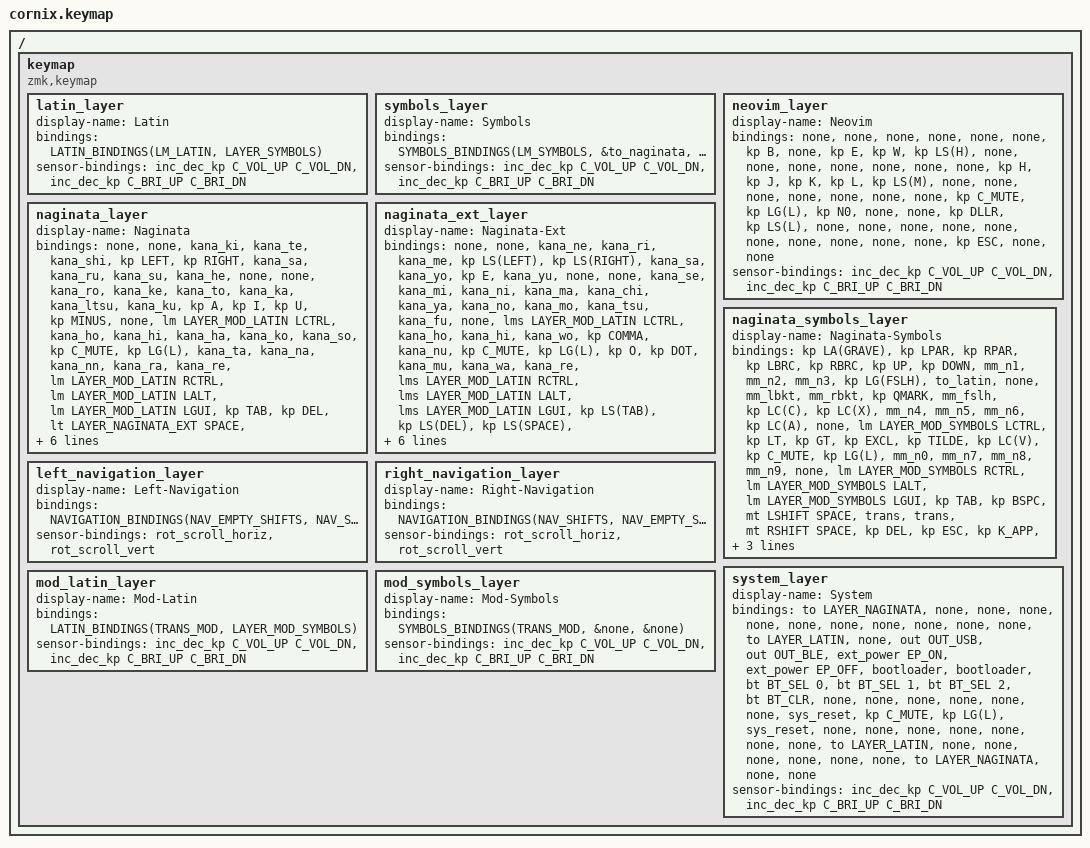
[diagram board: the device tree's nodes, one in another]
/*
 * Copyright (c) 2020 The ZMK Contributors
 *
 * SPDX-License-Identifier: MIT
 */

#include "zmk-helpers/helper.h"
#include "includes/cornix54.h"
#include "includes/base_keys.h"
#include "includes/navigation_keys.h"
#include "includes/layers.h"
#include "includes/settings.h"
#include <behaviors.dtsi>
#include <dt-bindings/zmk/bt.h>
#include <dt-bindings/zmk/ext_power.h>
#include <dt-bindings/zmk/keys.h>
#include <dt-bindings/zmk/outputs.h>
#include <dt-bindings/zmk/pointing.h>

#include "includes/combos.dtsi"
#include "includes/naginata_macros.dtsi"
#include "includes/naginata_combos.dtsi"
#include "includes/behaviors.dtsi"

/ {
    keymap {
        compatible = "zmk,keymap";

        latin_layer {
            display-name = "Latin";

            // ------------------------------------------------------------------------------------------------------------
            // |       |   B   |  L  |  D  |  W   |  Z   |                   | , !  |  F   |  O   |  U   |  J   |       |
            // |   `   |   N   |  R  |  T  |  S   |  G   |                   |  Y   |  H   |  A   |  E   |  I   |   '   |
            // |LM8/CTL|   Q   |  X  |  P  |  C   |  V   |        |  |       |  K   |  M   | . ?  | - _  | / \  |LM8/CTL|
            // |LM8/ALT|LM8/GUI| TAB | DEL |SFT/SP|L1/RET|                   |L1/RET|SFT/SP| BSPC | ESC  | MENU |LM8/ALT|
            // ------------------------------------------------------------------------------------------------------------

            bindings = <
LATIN_BINDINGS(LM_LATIN, LAYER_SYMBOLS)
            >;
            sensor-bindings = <&inc_dec_kp C_VOL_UP C_VOL_DN &inc_dec_kp C_BRI_UP C_BRI_DN>;
        };

        symbols_layer {
            display-name = "Symbols";

            // ------------------------------------------------------------------------------------------------------------
            // | TO_JA |   {   |  }  |  [   |  ]   |  ^   |                   |  %   |  #   |  <  |  >  |  $   |IME_TG |
            // |       |   ;   |  |  |  &   |  0   |  :   |                   |  @   |  1   |  (  |  )  |  =   |       |
            // |LM9/CTL|   6   |  7  |  8   |  9   |  +   |        |  |       |  *   |  2   |  3  |  4  |  5   |LM9/CTL|
            // |LM9/ALT|LM9/GUI| TAB | BSPC |SFT/SP| (RET)|                   | (RET)|SFT/SP| DEL | ESC | MENU |LM9/ALT|
            // ------------------------------------------------------------------------------------------------------------

            bindings = <
SYMBOLS_BINDINGS(LM_SYMBOLS, &to_naginata, &kp LA(GRAVE))
            >;
            sensor-bindings = <&inc_dec_kp C_VOL_UP C_VOL_DN &inc_dec_kp C_BRI_UP C_BRI_DN>;
        };

        neovim_layer {
            display-name = "Neovim";

            // ------------------------------------------------------------------------------------------------------------
            // |       |     |     |      |      |      |                   |  b   |      |  e   |  w   |  H   |      |
            // |       |     |     |      |      |      |                   |  h   |  j   |  k   |  l   |  M   |      |
            // |       |     |     |      |      |      |        |  |       |  0   |      |      |  $   |  L   |      |
            // |       |     |     |      |      |      |                   |      |      |      | ESC  |      |      |
            // ------------------------------------------------------------------------------------------------------------

            bindings = <
&none   &none   &none   &none   &none   &none                   &kp B   &none   &kp E  &kp W      &kp LS(H)  &none
&none   &none   &none   &none   &none   &none                   &kp H   &kp J   &kp K  &kp L      &kp LS(M)  &none
&none   &none   &none   &none   &none   &none   &kp C_MUTE &kp LG(L)   &kp N0  &none   &none  &kp DLLR   &kp LS(L)  &none
&none   &none   &none   &none   &none   &none                   &none   &none   &none  &kp ESC    &none      &none
            >;
            sensor-bindings = <&inc_dec_kp C_VOL_UP C_VOL_DN &inc_dec_kp C_BRI_UP C_BRI_DN>;
        };

        naginata_layer {
            display-name = "Naginata";

            // ------------------------------------------------------------------------------------------------------------
            // |       |       |  き  |  て  |  し  |  <- |                   |  ->  |  さ  |  る  |  す  |  へ  |       |
            // |       |   ろ  |  け  |  と  |  か  |  っ  |                   |  く  |  あ  |  い  |  う  |  ー  |       |
            // |LM8/CTL|   ほ  |  ひ  |  は  |  こ  |  そ  |        |  |       |  た  |  な  |  ん  |  ら  |  れ  |LM8/CTL|
            // |LM8/ALT|LM8/GUI| TAB | DEL  |L4/SP |L5/RET|                  |L5/RET|L4/SP| BSPC | ESC  | MENU |LM8/ALT|
            // ------------------------------------------------------------------------------------------------------------

            bindings = <
&none                   &none                 &kana_ki  &kana_te  &kana_shi  &kp LEFT                   &kp RIGHT  &kana_sa  &kana_ru  &kana_su     &kana_he   &none
&none                   &kana_ro              &kana_ke  &kana_to  &kana_ka   &kana_ltsu                 &kana_ku   &kp A     &kp I     &kp U        &kp MINUS  &none
&lm LAYER_MOD_LATIN LCTRL &kana_ho              &kana_hi  &kana_ha  &kana_ko   &kana_so   &kp C_MUTE &kp LG(L) &kana_ta   &kana_na  &kana_nn  &kana_ra     &kana_re   &lm LAYER_MOD_LATIN RCTRL
&lm LAYER_MOD_LATIN LALT  &lm LAYER_MOD_LATIN LGUI &kp TAB  &kp DEL &lt LAYER_NAGINATA_EXT SPACE &lt LAYER_NAGINATA_SYMBOLS RET  &lt LAYER_NAGINATA_SYMBOLS RET &lt LAYER_NAGINATA_EXT SPACE &kp BSPC &kp ESC &kp K_APP &lm LAYER_MOD_LATIN RALT
            >;
            sensor-bindings = <&inc_dec_kp C_VOL_UP C_VOL_DN &inc_dec_kp C_BRI_UP C_BRI_DN>;
        };

        naginata_ext_layer {
            display-name = "Naginata-Ext";

            // ------------------------------------------------------------------------------------------------------------
            // |        |        |  ね  |  り  |  め  |   S+<- |                   |  S+->  |  さ  |  よ   |  え  |  ゆ  |       |
            // |        |   せ   |  み  |  に  |  ま  |    ち   |                   |   や   |  の  |  も   |  つ  |  ふ  |       |
            // |LMS8/CTL|   ほ   |  ひ  |  を  |  、  |    ぬ   |        |  |       |   お   |  。  |  む   |  わ  |  れ  |LMS8/CTL|
            // |LMS8/ALT|LMS8/GUI|S+TAB|S+DEL | S+SP |L5/S+RET|                   |L5/S+RET| S+SP |S+BSPC| S+ESC|S+MENU|LMS8/ALT|
            // ------------------------------------------------------------------------------------------------------------

            bindings = <
&none                   &none                  &kana_ne  &kana_ri  &kana_me   &kp LS(LEFT)               &kp LS(RIGHT)  &kana_sa  &kana_yo  &kp E      &kana_yu  &none
&none                   &kana_se               &kana_mi  &kana_ni  &kana_ma   &kana_chi                  &kana_ya       &kana_no  &kana_mo  &kana_tsu  &kana_fu  &none
&lms LAYER_MOD_LATIN LCTRL &kana_ho              &kana_hi  &kana_wo  &kp COMMA  &kana_nu   &kp C_MUTE &kp LG(L) &kp O  &kp DOT   &kana_mu  &kana_wa   &kana_re  &lms LAYER_MOD_LATIN RCTRL
&lms LAYER_MOD_LATIN LALT  &lms LAYER_MOD_LATIN LGUI &kp LS(TAB) &kp LS(DEL) &kp LS(SPACE)  &lt LAYER_NAGINATA_SYMBOLS LS(RET)  &lt LAYER_NAGINATA_SYMBOLS LS(RET)  &kp LS(SPACE)  &kp LS(BSPC) &kp LS(ESC) &kp LS(K_APP) &lms LAYER_MOD_LATIN RALT
            >;
            sensor-bindings = <&inc_dec_kp C_VOL_UP C_VOL_DN &inc_dec_kp C_BRI_UP C_BRI_DN>;
        };

        naginata_symbols_layer {
            display-name = "Naginata-Symbols";

            // ------------------------------------------------------------------------------------------------------------
            // |IME_TG |   (   | ) |  {   |  }   |  UP  |                   | DOWN |  1   |  2   |  3   |RECONV|TO_LATIN|
            // |       |   [   | ] |  ?   |  ・  |CPY(C)|                   |CUT(X)|  4   |  5   |  6   |ALL(A)|       |
            // |LM10/CTL|  <   | > |  !   |  ~   |PST(V)|        |  |       |  0   |  7   |  8   |  9   |      |LM10/CTL|
            // |LM10/ALT|LM10/GUI|TAB|BSPC|SFT/SP|(RET)|                   | (RET)|SFT/SP| DEL  | ESC  | MENU |LM10/ALT|
            // ------------------------------------------------------------------------------------------------------------

            bindings = <
&kp LA(GRAVE)               &kp LPAR                  &kp RPAR &kp LBRC  &kp RBRC  &kp UP                    &kp DOWN  &mm_n1  &mm_n2  &mm_n3  &kp LG(FSLH) &to_latin
&none                       &mm_lbkt                  &mm_rbkt &kp QMARK &mm_fslh  &kp LC(C)                 &kp LC(X) &mm_n4  &mm_n5  &mm_n6  &kp LC(A)    &none
&lm LAYER_MOD_SYMBOLS LCTRL &kp LT                    &kp GT   &kp EXCL  &kp TILDE &kp LC(V)  &kp C_MUTE &kp LG(L) &mm_n0  &mm_n7  &mm_n8  &mm_n9  &none        &lm LAYER_MOD_SYMBOLS RCTRL
&lm LAYER_MOD_SYMBOLS LALT  &lm LAYER_MOD_SYMBOLS LGUI &kp TAB &kp BSPC  &mt LSHIFT SPACE &trans     &trans  &mt RSHIFT SPACE  &kp DEL  &kp ESC &kp K_APP &lm LAYER_MOD_SYMBOLS RALT
            >;
            sensor-bindings = <&inc_dec_kp C_VOL_UP C_VOL_DN &inc_dec_kp C_BRI_UP C_BRI_DN>;
        };

        left_navigation_layer {
            display-name = "Left-Navigation";

            // ------------------------------------------------------------------------------------------------------------
            // | TO_JA |  F1 |  F2 |  F3  |  F4  |  F5  |                   |PRTSCN| HOME |  UP  |  END |PG_UP |TO_EN |
            // | PAUSE |  F6 |  F7 |  F8  |  F9  |  F10 |                   | CAPS | LEFT | DOWN | RIGHT|PG_DN | RGUI |
            // | LCTRL | F11 |     |      |      |  F12 |        |  |       |SCRLCK|LSHIFT|      |RSHIFT|INSERT| RCTRL |
            // | LALT  | LGUI| TAB |  DEL |SFT/SP|TO_SYS|                   | RET  |SFT/SP| BSPC | ESC  | MENU | RALT |
            // ------------------------------------------------------------------------------------------------------------

            bindings = <
NAVIGATION_BINDINGS(NAV_EMPTY_SHIFTS, NAV_SHIFTS, &to LAYER_SYSTEM, &kp RET)
            >;
            sensor-bindings = <&rot_scroll_horiz &rot_scroll_vert>;
        };

        right_navigation_layer {
            display-name = "Right-Navigation";

            // ------------------------------------------------------------------------------------------------------------
            // | TO_JA |  F1 |  F2 |  F3  |  F4  |  F5  |                   |PRTSCN| HOME |  UP  |  END |PG_UP |TO_EN |
            // | PAUSE |  F6 |  F7 |  F8  |  F9  |  F10 |                   | CAPS | LEFT | DOWN | RIGHT|PG_DN | RGUI |
            // | LCTRL | F11 |LSHIFT|     |RSHIFT|  F12 |        |  |       |SCRLCK|      |      |      |INSERT| RCTRL |
            // | LALT  | LGUI| TAB |  DEL |SFT/SP| RET  |                   |TO_SYS|SFT/SP| BSPC | ESC  | MENU | RALT |
            // ------------------------------------------------------------------------------------------------------------

            bindings = <
NAVIGATION_BINDINGS(NAV_SHIFTS, NAV_EMPTY_SHIFTS, &kp RET, &to LAYER_SYSTEM)
            >;
            sensor-bindings = <&rot_scroll_horiz &rot_scroll_vert>;
        };

        system_layer {
            display-name = "System";

            // ------------------------------------------------------------------------------------------------------------
            // | TO_JA |      |     |      |      |       |                   |       |      |      |      |      | TO_EN |
            // |       |OUTUSB|OUTBLE|EP_ON|EP_OFF|BOOT(L)|                   |BOOT(R)| BT 1 | BT 2 | BT 3 |BTCLR |       |
            // |       |      |     |      |      |RST(L) |        |  |       |RST(R) |      |      |      |      |       |
            // |       |      |TO_EN|      |      |       |                   |       |      |      |TO_JA |      |       |
            // ------------------------------------------------------------------------------------------------------------

            bindings = <
&to LAYER_NAGINATA &none &none &none &none &none &none &none &none &none &none &to LAYER_LATIN
&none   &out OUT_USB  &out OUT_BLE  &ext_power EP_ON  &ext_power EP_OFF  &bootloader                   &bootloader  &bt BT_SEL 0  &bt BT_SEL 1  &bt BT_SEL 2  &bt BT_CLR    &none
&none   &none         &none         &none             &none              &sys_reset    &kp C_MUTE &kp LG(L)   &sys_reset   &none         &none         &none         &none         &none
&none   &none         &to LAYER_LATIN &none            &none              &none                         &none        &none         &none         &to LAYER_NAGINATA &none         &none
            >;
            sensor-bindings = <&inc_dec_kp C_VOL_UP C_VOL_DN &inc_dec_kp C_BRI_UP C_BRI_DN>;
        };

        mod_latin_layer {
            display-name = "Mod-Latin";

            // ------------------------------------------------------------------------------------------------------------
            // |       |  B  |  L  |  D   |  W   |  Z   |                   | , !  |  F   |  O   |  U   |   J  |       |
            // |   `   |  N  |  R  |  T   |  S   |  G   |                   |  Y   |  H   |  A   |  E   |   I  |   '   |
            // |(CTRL) |  Q  |  X  |  P   |  C   |  V   |        |  |       |  K   |  M   | . ?  | - _  | / \  |(CTRL) |
            // | (ALT) |(GUI)| TAB | DEL  |SFT/SP|L9/RET|                   |L9/RET|SFT/SP| BSPC | ESC  | MENU |(ALT)  |
            // ------------------------------------------------------------------------------------------------------------

            bindings = <
LATIN_BINDINGS(TRANS_MOD, LAYER_MOD_SYMBOLS)
            >;
            sensor-bindings = <&inc_dec_kp C_VOL_UP C_VOL_DN &inc_dec_kp C_BRI_UP C_BRI_DN>;
        };

        mod_symbols_layer {
            display-name = "Mod-Symbols";

            // ------------------------------------------------------------------------------------------------------------
            // |       |  {  |  }  |  [   |  ]   |  ^   |                   |  %   |  #   |  <   |  >   |  $   |       |
            // |       |  ;  |  |  |  &   |  0   |  :   |                   |  @   |  1   |  (   |  )   |  =   |       |
            // |(CTRL) |  6  |  7  |  8   |  9   |  +   |        |  |       |  *   |  2   |  3   |  4   |  5   |(CTRL) |
            // | (ALT) |(GUI)| TAB | BSPC |SFT/SP| (RET)|                   | (RET)|SFT/SP| DEL  | ESC  | MENU | (ALT) |
            // ------------------------------------------------------------------------------------------------------------

            bindings = <
SYMBOLS_BINDINGS(TRANS_MOD, &none, &none)
            >;
            sensor-bindings = <&inc_dec_kp C_VOL_UP C_VOL_DN &inc_dec_kp C_BRI_UP C_BRI_DN>;
        };
    };
};
